# SERDES_10G0 register map
Vendor: Texas Instruments
Registers are 32-bit, access per field, reset 0x0 unless marked. A register's access mark holds for its fields unless they carry their own. Offsets are as the file gives them; [hi:lo] are bit positions.

## SERDES_10G0 (part 3 of 8)
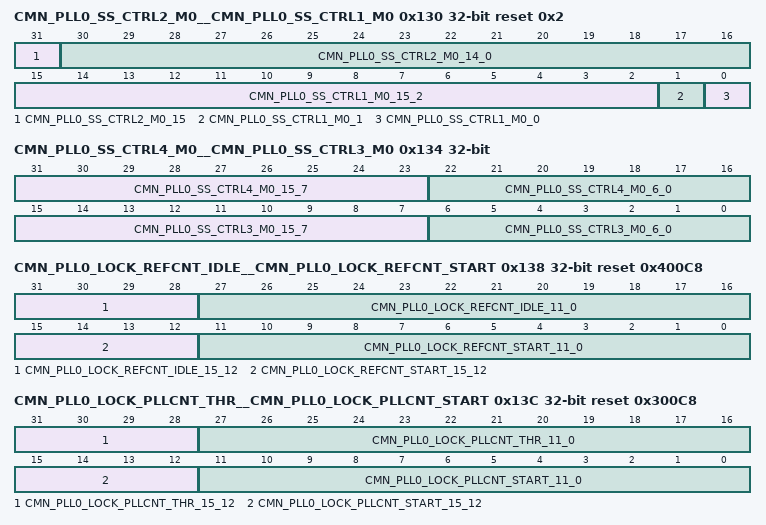
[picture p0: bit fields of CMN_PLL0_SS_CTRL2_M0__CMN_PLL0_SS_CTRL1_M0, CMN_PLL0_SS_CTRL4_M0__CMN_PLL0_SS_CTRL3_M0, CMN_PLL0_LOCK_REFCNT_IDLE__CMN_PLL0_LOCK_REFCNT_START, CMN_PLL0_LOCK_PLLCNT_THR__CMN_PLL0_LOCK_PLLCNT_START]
0x130 CMN_PLL0_SS_CTRL2_M0__CMN_PLL0_SS_CTRL1_M0 reset 0x2 — PLL 0 spread spectrum control register 1 mode 0
  [31] CMN_PLL0_SS_CTRL2_M0_15 ro — Reserved
  [30:16] CMN_PLL0_SS_CTRL2_M0_14_0 rw — Amplitude step size: Value of the amplitude_step_size pin on the spread spectrum waveform generator.
  [15:2] CMN_PLL0_SS_CTRL1_M0_15_2 ro — Reserved
  [1] CMN_PLL0_SS_CTRL1_M0_1 rw — Spread spectrum waveform generator disable: Setting this bit to a 1'b1 will disable the spread spectrum waveform generator.
  [0] CMN_PLL0_SS_CTRL1_M0_0 rw — Spread spectrum enable during VCO calibration : Setting this bit to a 1'b1 will enable the spread spectrum function while VCO calibration is taking place.
0x134 CMN_PLL0_SS_CTRL4_M0__CMN_PLL0_SS_CTRL3_M0 — PLL 0 spread spectrum control register 3 mode 0
  [31:23] CMN_PLL0_SS_CTRL4_M0_15_7 ro — Reserved
  [22:16] CMN_PLL0_SS_CTRL4_M0_6_0 rw — Time step size: Value for the time_step_size pin on the spread spectrum waveform generator.
  [15:7] CMN_PLL0_SS_CTRL3_M0_15_7 ro — Reserved
  [6:0] CMN_PLL0_SS_CTRL3_M0_6_0 rw — Number of steps: Value of the num_steps pin on the spread spectrum waveform generator.
0x138 CMN_PLL0_LOCK_REFCNT_IDLE__CMN_PLL0_LOCK_REFCNT_START reset 0x400C8 — PLL 0 lock reference counter start value register
  [31:28] CMN_PLL0_LOCK_REFCNT_IDLE_15_12 ro — Reserved
  [27:16] CMN_PLL0_LOCK_REFCNT_IDLE_11_0 rw — PLL lock reference counter idle value : This is the value used by the PLL lock detection logic to specify the number of reference clocks between each phase of counting PLL clocks.
  [15:12] CMN_PLL0_LOCK_REFCNT_START_15_12 ro — Reserved
  [11:0] CMN_PLL0_LOCK_REFCNT_START_11_0 rw — PLL lock reference counter start value : This is the value that is loaded into the PLL lock detect reference counter as the starting point for that counter, when checking for PLL lock.
0x13C CMN_PLL0_LOCK_PLLCNT_THR__CMN_PLL0_LOCK_PLLCNT_START reset 0x300C8 — PLL 0 lock PLL counter start value register
  [31:28] CMN_PLL0_LOCK_PLLCNT_THR_15_12 ro — Reserved
  [27:16] CMN_PLL0_LOCK_PLLCNT_THR_11_0 rw — PLL lock counter threshold value : This is the value used by the PLL lock detection logic to determine if the PLL has locked.
  [15:12] CMN_PLL0_LOCK_PLLCNT_START_15_12 ro — Reserved
  [11:0] CMN_PLL0_LOCK_PLLCNT_START_11_0 rw — PLL lock PLL counter start value : This is the value that is loaded into the PLL lock detect PLL counter as the starting point for that counter, when checking for PLL lock.
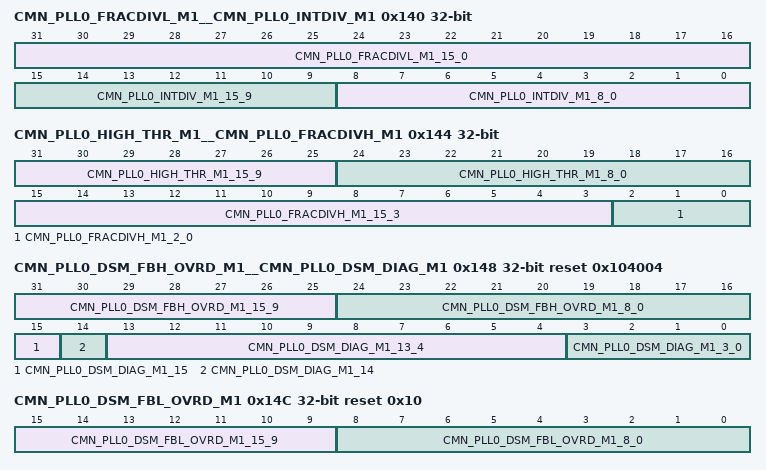
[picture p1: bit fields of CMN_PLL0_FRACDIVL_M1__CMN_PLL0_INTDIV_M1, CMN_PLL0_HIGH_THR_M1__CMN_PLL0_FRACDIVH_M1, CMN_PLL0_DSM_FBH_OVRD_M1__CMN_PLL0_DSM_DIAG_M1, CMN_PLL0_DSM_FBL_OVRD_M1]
0x140 CMN_PLL0_FRACDIVL_M1__CMN_PLL0_INTDIV_M1 — PLL 0 feedback divider integer register mode 1
  [31:16] CMN_PLL0_FRACDIVL_M1_15_0 rw — pll_fb_div_fractional: Value of the pll_fb_div_fractional[15:0] signal.
  [15:9] CMN_PLL0_INTDIV_M1_15_9 ro — Reserved
  [8:0] CMN_PLL0_INTDIV_M1_8_0 rw — pll_fb_div_integer value: Value of the pll_fb_div_integer signal.
0x144 CMN_PLL0_HIGH_THR_M1__CMN_PLL0_FRACDIVH_M1 — PLL 0 feedback divider fractional high register mode 1
  [31:25] CMN_PLL0_HIGH_THR_M1_15_9 ro — Reserved
  [24:16] CMN_PLL0_HIGH_THR_M1_8_0 rw — pll_fb_div_high_theshold: Value of the pll_fb_div_high_threshold signal.
  [15:3] CMN_PLL0_FRACDIVH_M1_15_3 ro — Reserved
  [2:0] CMN_PLL0_FRACDIVH_M1_2_0 rw — pll_fb_div_fractional: Value of the pll_fb_div_fractional[18:16] signal.
0x148 CMN_PLL0_DSM_FBH_OVRD_M1__CMN_PLL0_DSM_DIAG_M1 reset 0x104004 — PLL 0 delta sigma modulator diagnostics register mode 1
  [31:25] CMN_PLL0_DSM_FBH_OVRD_M1_15_9 ro — Reserved
  [24:16] CMN_PLL0_DSM_FBH_OVRD_M1_8_0 rw — PLL feedback divider high override value : When enabled by the PLL feedback divider override enable bit in the PLL 0 delta sigma modulator diagnostics register mode 0 on page 102, the value in this field will be used to override the value on the cmnda_pll0_fb_div_high signal.
  [15] CMN_PLL0_DSM_DIAG_M1_15 rw — Delta sigma bypass enable: When set to 1'b1, the delta sigma modulator will be bypassed, and the output will be the value specified for the internal pll_fb_div_integer signal.
  [14] CMN_PLL0_DSM_DIAG_M1_14 rw — PLL feedback divider override enable : When active (1'b1), the feedback divider low and high override values in the PLL 0 delta sigma modulator feedback divider value high override register mode 0 on page 102 and PLL 0 delta sigma modulator feedback divider value low override register mode 0 on page 102 registers will be used to override the feedback divider values driven to the analog.
  [13:4] CMN_PLL0_DSM_DIAG_M1_13_4 ro — Reserved
  [3:0] CMN_PLL0_DSM_DIAG_M1_3_0 rw — PLL feedback divider latency adjustment: This signal specifies a value to be subtracted from the feedback divider settings before they are output on the cmnda_pll0_fb_div_high and cmnda_pll0_fb_div_low signals.
0x14C CMN_PLL0_DSM_FBL_OVRD_M1 reset 0x10 — PLL 0 delta sigma modulator feedback divider value low override register mode 1
  [15:9] CMN_PLL0_DSM_FBL_OVRD_M1_15_9 ro — Reserved
  [8:0] CMN_PLL0_DSM_FBL_OVRD_M1_8_0 rw — PLL feedback divider low override value : When enabled by the PLL feedback divider override enable bit in the PLL 0 delta sigma modulator diagnostics register mode 0 on page 102, the value in this field will be used to override the value on the cmnda_pll0_fb_div_low signal.
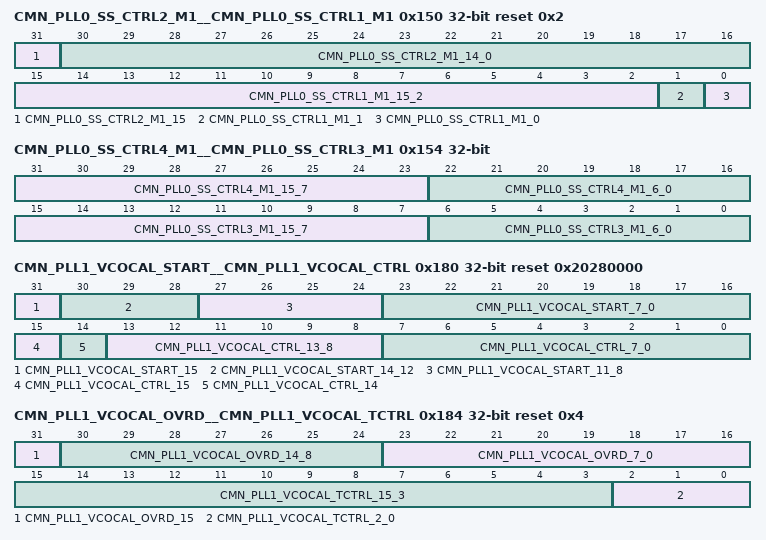
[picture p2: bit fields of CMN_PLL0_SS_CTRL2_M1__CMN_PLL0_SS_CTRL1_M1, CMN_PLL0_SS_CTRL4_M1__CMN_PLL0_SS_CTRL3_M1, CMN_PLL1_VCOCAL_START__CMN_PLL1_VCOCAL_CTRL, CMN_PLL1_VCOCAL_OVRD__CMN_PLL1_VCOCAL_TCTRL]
0x150 CMN_PLL0_SS_CTRL2_M1__CMN_PLL0_SS_CTRL1_M1 reset 0x2 — PLL 0 spread spectrum control register 1 mode 1
  [31] CMN_PLL0_SS_CTRL2_M1_15 ro — Reserved
  [30:16] CMN_PLL0_SS_CTRL2_M1_14_0 rw — Amplitude step size: Value of the amplitude_step_size pin on the spread spectrum waveform generator.
  [15:2] CMN_PLL0_SS_CTRL1_M1_15_2 ro — Reserved
  [1] CMN_PLL0_SS_CTRL1_M1_1 rw — Spread spectrum waveform generator disable: Setting this bit to a 1'b1 will disable the spread spectrum waveform generator.
  [0] CMN_PLL0_SS_CTRL1_M1_0 rw — Spread spectrum enable during VCO calibration : Setting this bit to a 1'b1 will enable the spread spectrum function while VCO calibration is taking place.
0x154 CMN_PLL0_SS_CTRL4_M1__CMN_PLL0_SS_CTRL3_M1 — PLL 0 spread spectrum control register 3 mode 1
  [31:23] CMN_PLL0_SS_CTRL4_M1_15_7 ro — Reserved
  [22:16] CMN_PLL0_SS_CTRL4_M1_6_0 rw — Time step size: Value for the time_step_size pin on the spread spectrum waveform generator.
  [15:7] CMN_PLL0_SS_CTRL3_M1_15_7 ro — Reserved
  [6:0] CMN_PLL0_SS_CTRL3_M1_6_0 rw — Number of steps: Value of the num_steps pin on the spread spectrum waveform generator.
0x180 CMN_PLL1_VCOCAL_START__CMN_PLL1_VCOCAL_CTRL reset 0x20280000 — PLL 1 VCO calibration control register
  [31] CMN_PLL1_VCOCAL_START_15 ro — Reserved
  [30:28] CMN_PLL1_VCOCAL_START_14_12 rw — VCO calibration initial step size control: This field specifies the initial step size for the VCO calibration state machine.
  [27:24] CMN_PLL1_VCOCAL_START_11_8 ro — Reserved
  [23:16] CMN_PLL1_VCOCAL_START_7_0 rw — VCO calibration code starting point value: This field specifies the starting VCO code that is used by the VCO calibration state machine.
  [15] CMN_PLL1_VCOCAL_CTRL_15 rw — Start VCO calibration: Activating (1'b1) this bit will start a VCO calibration process.
  [14] CMN_PLL1_VCOCAL_CTRL_14 ro — VCO calibration process done: This bit will be set to 1'b1 when the VCO calibration process is complete.
  [13:8] CMN_PLL1_VCOCAL_CTRL_13_8 ro — Reserved
  [7:0] CMN_PLL1_VCOCAL_CTRL_7_0 ro — VCO calibration code: This is the calibration code that was determined by the VCO calibration process.
0x184 CMN_PLL1_VCOCAL_OVRD__CMN_PLL1_VCOCAL_TCTRL reset 0x4 — PLL 1 VCO calibration timer control register
  [31] CMN_PLL1_VCOCAL_OVRD_15 rw — VCO calibration code override enable: Activating (1'b1) this bit allows the VCO code determined during the automatic VCO calibration process to be overridden by the value driven by the VCO calibration code override value field in this register.
  [30:24] CMN_PLL1_VCOCAL_OVRD_14_8 ro — Reserved
  [23:16] CMN_PLL1_VCOCAL_OVRD_7_0 rw — VCO calibration code override value: This field is used to override the VCO code determined during the automatic VCO calibration process.
  [15:3] CMN_PLL1_VCOCAL_TCTRL_15_3 ro — Reserved
  [2:0] CMN_PLL1_VCOCAL_TCTRL_2_0 rw — VCO calibration initial time scale control: This field specifies the calibration start time scaling factor applied to the VCO calibration when running the initial step size for the calibration code if not set to 1.
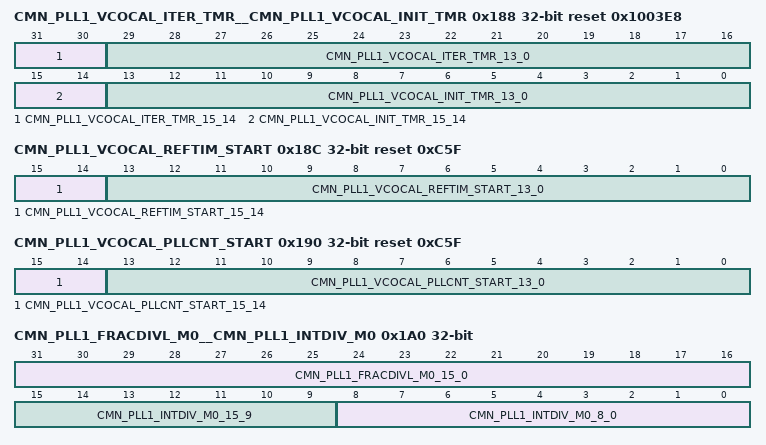
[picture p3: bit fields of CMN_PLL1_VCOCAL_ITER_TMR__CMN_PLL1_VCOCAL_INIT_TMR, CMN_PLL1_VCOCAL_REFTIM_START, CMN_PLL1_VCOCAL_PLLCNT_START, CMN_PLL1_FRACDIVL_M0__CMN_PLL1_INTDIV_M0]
0x188 CMN_PLL1_VCOCAL_ITER_TMR__CMN_PLL1_VCOCAL_INIT_TMR reset 0x1003E8 — PLL 1 VCO calibration initialization timer register
  [31:30] CMN_PLL1_VCOCAL_ITER_TMR_15_14 ro — Reserved
  [29:16] CMN_PLL1_VCOCAL_ITER_TMR_13_0 rw — Iteration wait timer value: This is the number of clocks to wait between when a calibration code is driven to the analog, and when the clock rates are measured.
  [15:14] CMN_PLL1_VCOCAL_INIT_TMR_15_14 ro — Reserved
  [13:0] CMN_PLL1_VCOCAL_INIT_TMR_13_0 rw — Initialization wait timer value: This is the number of clocks to wait between when the analog VCO calibration circuits are enabled, and when the first calibration code is driven to the analog.
0x18C CMN_PLL1_VCOCAL_REFTIM_START reset 0xC5F — PLL 1 VCO calibration reference clock timer start value register
  [15:14] CMN_PLL1_VCOCAL_REFTIM_START_15_14 ro — Reserved
  [13:0] CMN_PLL1_VCOCAL_REFTIM_START_13_0 rw — PLL VCO calibration reference clock timer start value : This is the value that is loaded into the reference clock timer as the starting point for that timer, when running VCO calibration.
0x190 CMN_PLL1_VCOCAL_PLLCNT_START reset 0xC5F — PLL 1 VCO calibration PLL clock counter start value register
  [15:14] CMN_PLL1_VCOCAL_PLLCNT_START_15_14 ro — Reserved
  [13:0] CMN_PLL1_VCOCAL_PLLCNT_START_13_0 rw — PLL VCO calibration PLL clock counter start value : This is the value that is loaded into the PLL clock counter as the starting point for that counter, when running VCO calibration.
0x1A0 CMN_PLL1_FRACDIVL_M0__CMN_PLL1_INTDIV_M0 — PLL 1 feedback divider integer register mode 0
  [31:16] CMN_PLL1_FRACDIVL_M0_15_0 rw — pll_fb_div_fractional: Value of the pll_fb_div_fractional[15:0] signal.
  [15:9] CMN_PLL1_INTDIV_M0_15_9 ro — Reserved
  [8:0] CMN_PLL1_INTDIV_M0_8_0 rw — pll_fb_div_integer value: Value of the pll_fb_div_integer signal.
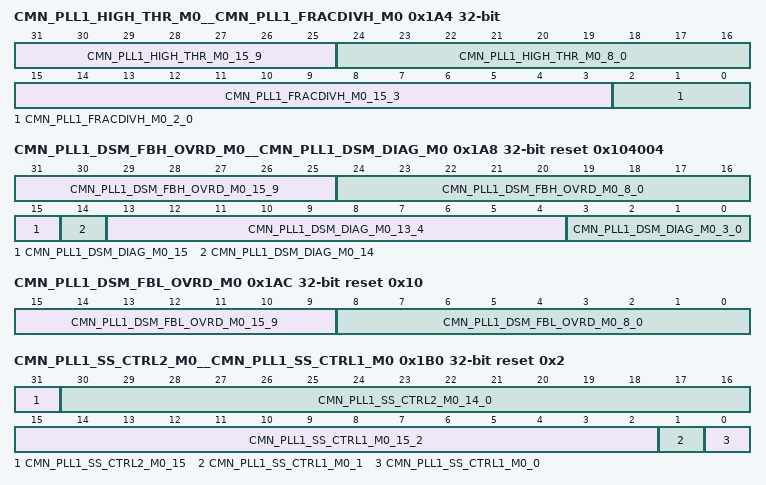
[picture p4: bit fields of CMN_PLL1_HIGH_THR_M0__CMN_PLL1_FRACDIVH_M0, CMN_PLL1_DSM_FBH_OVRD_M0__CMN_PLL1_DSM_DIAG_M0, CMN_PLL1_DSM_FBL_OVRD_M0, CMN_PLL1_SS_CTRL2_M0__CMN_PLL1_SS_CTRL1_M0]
0x1A4 CMN_PLL1_HIGH_THR_M0__CMN_PLL1_FRACDIVH_M0 — PLL 1 feedback divider fractional high register mode 0
  [31:25] CMN_PLL1_HIGH_THR_M0_15_9 ro — Reserved
  [24:16] CMN_PLL1_HIGH_THR_M0_8_0 rw — pll_fb_div_high_theshold: Value of the pll_fb_div_high_threshold signal.
  [15:3] CMN_PLL1_FRACDIVH_M0_15_3 ro — Reserved
  [2:0] CMN_PLL1_FRACDIVH_M0_2_0 rw — pll_fb_div_fractional: Value of the pll_fb_div_fractional[18:16] signal.
0x1A8 CMN_PLL1_DSM_FBH_OVRD_M0__CMN_PLL1_DSM_DIAG_M0 reset 0x104004 — PLL 1 delta sigma modulator diagnostics register mode 0
  [31:25] CMN_PLL1_DSM_FBH_OVRD_M0_15_9 ro — Reserved
  [24:16] CMN_PLL1_DSM_FBH_OVRD_M0_8_0 rw — PLL feedback divider high override value : When enabled by the PLL feedback divider override enable bit in the PLL 1 delta sigma modulator diagnostics register mode 0 on page 111, the value in this field will be used to override the value on the cmnda_pll1_fb_div_high signal.
  [15] CMN_PLL1_DSM_DIAG_M0_15 rw — Delta sigma bypass enable: When set to 1'b1, the delta sigma modulator will be bypassed, and the output will be the value specified for the internal pll_fb_div_integer signal.
  [14] CMN_PLL1_DSM_DIAG_M0_14 rw — PLL feedback divider override enable : When active (1'b1), the feedback divider low and high override values in the PLL 1 delta sigma modulator feedback divider value high override register mode 0 on page 111 and PLL 1 delta sigma modulator feedback divider value low override register mode 0 on page 111 registers will be used to override the feedback divider values driven to the analog.
  [13:4] CMN_PLL1_DSM_DIAG_M0_13_4 ro — Reserved
  [3:0] CMN_PLL1_DSM_DIAG_M0_3_0 rw — PLL feedback divider latency adjustment: This signal specifies a value to be subtracted from the feedback divider settings before they are output on the cmnda_pll1_fb_div_high and cmnda_pll1_fb_div_low signals.
0x1AC CMN_PLL1_DSM_FBL_OVRD_M0 reset 0x10 — PLL 1 delta sigma modulator feedback divider value low override register mode 0
  [15:9] CMN_PLL1_DSM_FBL_OVRD_M0_15_9 ro — Reserved
  [8:0] CMN_PLL1_DSM_FBL_OVRD_M0_8_0 rw — PLL feedback divider low override value : When enabled by the PLL feedback divider override enable bit in the PLL 1 delta sigma modulator diagnostics register mode 0 on page 111, the value in this field will be used to override the value on the cmnda_pll1_fb_div_low signal.
0x1B0 CMN_PLL1_SS_CTRL2_M0__CMN_PLL1_SS_CTRL1_M0 reset 0x2 — PLL 1 spread spectrum control register 1 mode 0
  [31] CMN_PLL1_SS_CTRL2_M0_15 ro — Reserved
  [30:16] CMN_PLL1_SS_CTRL2_M0_14_0 rw — Amplitude step size: Value of the amplitude_step_size pin on the spread spectrum waveform generator.
  [15:2] CMN_PLL1_SS_CTRL1_M0_15_2 ro — Reserved
  [1] CMN_PLL1_SS_CTRL1_M0_1 rw — Spread spectrum waveform generator disable: Setting this bit to a 1'b1 will disable the spread spectrum waveform generator.
  [0] CMN_PLL1_SS_CTRL1_M0_0 rw — Spread spectrum enable during VCO calibration : Setting this bit to a 1'b1 will enable the spread spectrum function while VCO calibration is taking place.
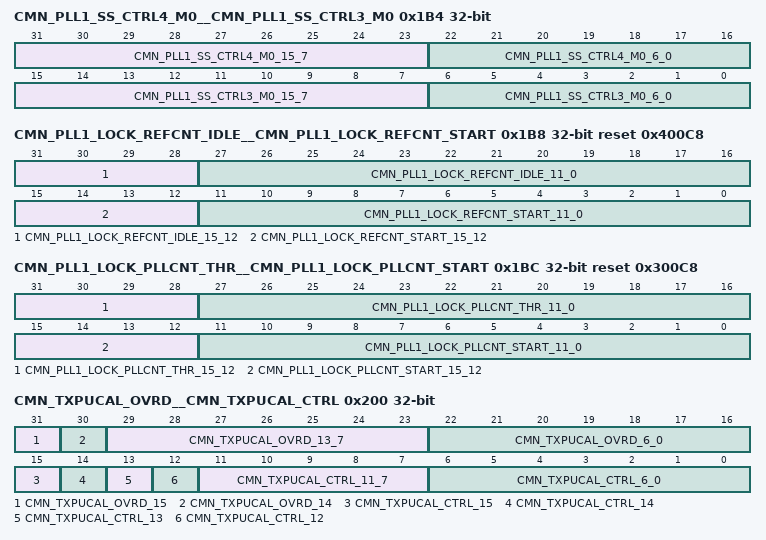
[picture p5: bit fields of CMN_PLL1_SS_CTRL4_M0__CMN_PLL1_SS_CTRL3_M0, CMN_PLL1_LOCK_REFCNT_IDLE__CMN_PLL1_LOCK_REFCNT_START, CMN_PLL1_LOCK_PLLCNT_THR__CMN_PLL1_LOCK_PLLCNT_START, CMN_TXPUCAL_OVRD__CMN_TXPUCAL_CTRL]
0x1B4 CMN_PLL1_SS_CTRL4_M0__CMN_PLL1_SS_CTRL3_M0 — PLL 1 spread spectrum control register 3 mode 0
  [31:23] CMN_PLL1_SS_CTRL4_M0_15_7 ro — Reserved
  [22:16] CMN_PLL1_SS_CTRL4_M0_6_0 rw — Time step size: Value for the time_step_size pin on the spread spectrum waveform generator.
  [15:7] CMN_PLL1_SS_CTRL3_M0_15_7 ro — Reserved
  [6:0] CMN_PLL1_SS_CTRL3_M0_6_0 rw — Number of steps: Value of the num_steps pin on the spread spectrum waveform generator.
0x1B8 CMN_PLL1_LOCK_REFCNT_IDLE__CMN_PLL1_LOCK_REFCNT_START reset 0x400C8 — PLL 1 lock reference counter start value register
  [31:28] CMN_PLL1_LOCK_REFCNT_IDLE_15_12 ro — Reserved
  [27:16] CMN_PLL1_LOCK_REFCNT_IDLE_11_0 rw — PLL lock reference counter idle value : This is the value used by the PLL lock detection logic to specify the number of reference clocks between each phase of counting PLL clocks.
  [15:12] CMN_PLL1_LOCK_REFCNT_START_15_12 ro — Reserved
  [11:0] CMN_PLL1_LOCK_REFCNT_START_11_0 rw — PLL lock reference counter start value : This is the value that is loaded into the PLL lock detect reference counter as the starting point for that counter, when checking for PLL lock.
0x1BC CMN_PLL1_LOCK_PLLCNT_THR__CMN_PLL1_LOCK_PLLCNT_START reset 0x300C8 — PLL 1 lock PLL counter start value register
  [31:28] CMN_PLL1_LOCK_PLLCNT_THR_15_12 ro — Reserved
  [27:16] CMN_PLL1_LOCK_PLLCNT_THR_11_0 rw — PLL lock counter threshold value : This is the value used by the PLL lock detection logic to determine if the PLL has locked.
  [15:12] CMN_PLL1_LOCK_PLLCNT_START_15_12 ro — Reserved
  [11:0] CMN_PLL1_LOCK_PLLCNT_START_11_0 rw — PLL lock PLL counter start value : This is the value that is loaded into the PLL lock detect PLL counter as the starting point for that counter, when checking for PLL lock.
0x200 CMN_TXPUCAL_OVRD__CMN_TXPUCAL_CTRL — TX pull-up resistor calibration control register
  [31] CMN_TXPUCAL_OVRD_15 rw — Resistor code override enable: Activation (1'b1) of this register bit allows the resistor codes determined during the automatic resistor calibration process to be overridden.
  [30] CMN_TXPUCAL_OVRD_14 rw — Analog calibration enable override: Activation (1'b1) of this register bit will force the analog calibration circuits to be enabled by activating the cmnda_rescal_en_tx_useg enable and the cmnda_rescal_clk_tx_useg clock.
  [29:23] CMN_TXPUCAL_OVRD_13_7 ro — Reserved
  [22:16] CMN_TXPUCAL_OVRD_6_0 rw — Resistor code override value: These bits are used to override the resistor code determined during the automatic resistor calibration process.
  [15] CMN_TXPUCAL_CTRL_15 rw — Start resistor calibration: Activating (1'b1) this bit will start the resistor calibration process.
  [14] CMN_TXPUCAL_CTRL_14 ro — Resistor calibration process done: This bit will be set to 1'b1 when the resistor calibration process is complete.
  [13] CMN_TXPUCAL_CTRL_13 ro — No analog calibration response : This signal indicates that the calibration function has gone through the entire calibration process, reached the final calibration value, and the analog has not responded indicating that a valid calibration value has been reached.
  [12] CMN_TXPUCAL_CTRL_12 ro — Current analog comparator response: This is the current state of the analog comparator response signal (cmnda_rescal_comp_tx_useg).
  [11:7] CMN_TXPUCAL_CTRL_11_7 ro — Reserved
  [6:0] CMN_TXPUCAL_CTRL_6_0 ro — Resistor calibration code: This is the calibration code that was determined by the resistor calibration process.
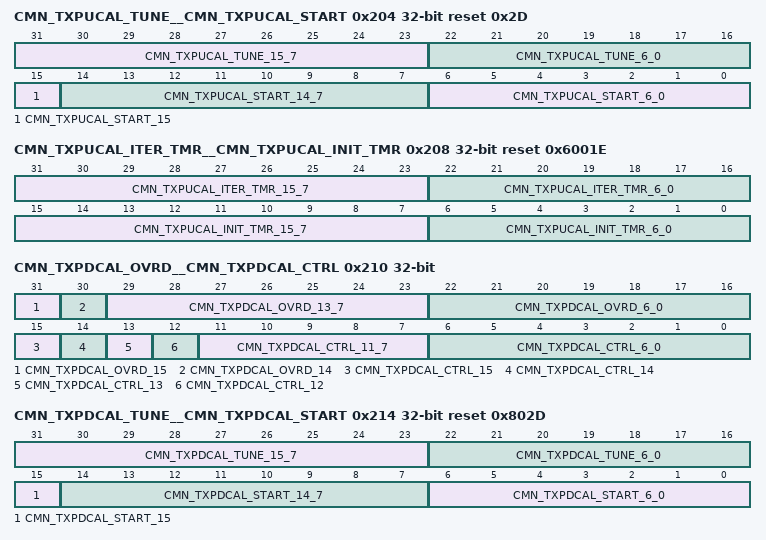
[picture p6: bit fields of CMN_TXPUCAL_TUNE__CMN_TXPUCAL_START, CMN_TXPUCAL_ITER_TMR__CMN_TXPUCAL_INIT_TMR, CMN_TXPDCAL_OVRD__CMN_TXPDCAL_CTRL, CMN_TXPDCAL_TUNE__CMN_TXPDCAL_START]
0x204 CMN_TXPUCAL_TUNE__CMN_TXPUCAL_START reset 0x2D — TX pull-up resistor calibration start register
  [31:23] CMN_TXPUCAL_TUNE_15_7 ro — Reserved
  [22:16] CMN_TXPUCAL_TUNE_6_0 rw — Resistor calibration tune value: The value of this field is added to the automatically calibrated code, or the override code if override is enabled.
  [15] CMN_TXPUCAL_START_15 rw — Resistor calibration direction: This controls the direction that the automatic calibration process steps the calibration codes in.
  [14:7] CMN_TXPUCAL_START_14_7 ro — Reserved
  [6:0] CMN_TXPUCAL_START_6_0 rw — Start resistor calibration code: This is the calibration code that the resistor calibration process starts with when automatic calibration is run.
0x208 CMN_TXPUCAL_ITER_TMR__CMN_TXPUCAL_INIT_TMR reset 0x6001E — TX pull-up resistor calibration initialization timer register
  [31:23] CMN_TXPUCAL_ITER_TMR_15_7 ro — Reserved
  [22:16] CMN_TXPUCAL_ITER_TMR_6_0 rw — Iteration wait timer value: This is the number of cmn_ref_clk clocks to wait between when a value is placed on the resistor selection bus going to the analog, and when the comparator value coming from the analog circuits can be checked.
  [15:7] CMN_TXPUCAL_INIT_TMR_15_7 ro — Reserved
  [6:0] CMN_TXPUCAL_INIT_TMR_6_0 rw — Initialization wait timer value: This is the number of cmn_ref_clk clocks to wait between when the analog resistor calibration circuits are enabled, and when the first resistor selection values are placed on the resistor selection bus, going to the analog.
0x210 CMN_TXPDCAL_OVRD__CMN_TXPDCAL_CTRL — TX pull-down resistor calibration control register
  [31] CMN_TXPDCAL_OVRD_15 rw — Resistor code override enable: Activation (1'b1) of this register bit allows the resistor codes determined during the automatic resistor calibration process to be overridden.
  [30] CMN_TXPDCAL_OVRD_14 rw — Analog calibration enable override: Activation (1'b1) of this register bit will force the analog calibration circuits to be enabled by activating the cmnda_rescal_en_tx_dseg enable and the cmnda_rescal_clk_tx_dseg clock.
  [29:23] CMN_TXPDCAL_OVRD_13_7 ro — Reserved
  [22:16] CMN_TXPDCAL_OVRD_6_0 rw — Resistor code override value: These bits are used to override the resistor code determined during the automatic resistor calibration process.
  [15] CMN_TXPDCAL_CTRL_15 rw — Start resistor calibration: Activating (1'b1) this bit will start the resistor calibration process.
  [14] CMN_TXPDCAL_CTRL_14 ro — Resistor calibration process done: This bit will be set to 1'b1 when the resistor calibration process is complete.
  [13] CMN_TXPDCAL_CTRL_13 ro — No analog calibration response : This signal indicates that the calibration function has gone through the entire calibration process, reached the final calibration value, and the analog has not responded indicating that a valid calibration value has been reached.
  [12] CMN_TXPDCAL_CTRL_12 ro — Current analog comparator response: This is the current state of the analog comparator response signal (cmnda_rescal_comp_tx_dseg).
  [11:7] CMN_TXPDCAL_CTRL_11_7 ro — Reserved
  [6:0] CMN_TXPDCAL_CTRL_6_0 ro — Resistor calibration code: This is the calibration code that was determined by the resistor calibration process.
0x214 CMN_TXPDCAL_TUNE__CMN_TXPDCAL_START reset 0x802D — TX pull-down resistor calibration start register
  [31:23] CMN_TXPDCAL_TUNE_15_7 ro — Reserved
  [22:16] CMN_TXPDCAL_TUNE_6_0 rw — Resistor calibration tune value: The value of this field is added to the automatically calibrated code, or the override code if override is enabled.
  [15] CMN_TXPDCAL_START_15 rw — Resistor calibration direction: This controls the direction that the automatic calibration process steps the calibration codes in.
  [14:7] CMN_TXPDCAL_START_14_7 ro — Reserved
  [6:0] CMN_TXPDCAL_START_6_0 rw — Start resistor calibration code: This is the calibration code that the resistor calibration process starts with when automatic calibration is run.
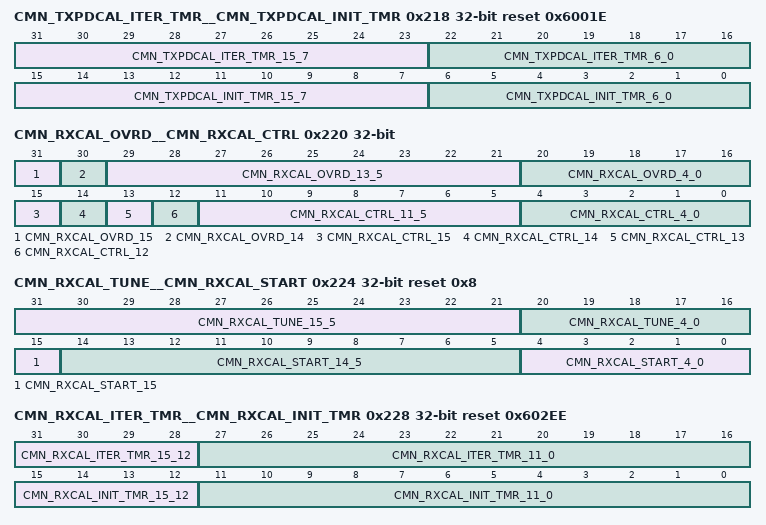
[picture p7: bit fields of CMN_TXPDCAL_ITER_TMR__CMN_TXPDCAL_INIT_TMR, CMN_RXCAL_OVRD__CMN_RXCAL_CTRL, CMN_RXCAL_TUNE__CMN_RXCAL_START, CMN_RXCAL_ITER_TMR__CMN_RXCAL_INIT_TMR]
0x218 CMN_TXPDCAL_ITER_TMR__CMN_TXPDCAL_INIT_TMR reset 0x6001E — TX pull-down resistor calibration initialization timer register
  [31:23] CMN_TXPDCAL_ITER_TMR_15_7 ro — Reserved
  [22:16] CMN_TXPDCAL_ITER_TMR_6_0 rw — Iteration wait timer value: This is the number of cmn_ref_clk clocks to wait between when a value is placed on the resistor selection bus going to the analog, and when the comparator value coming from the analog circuits can be checked.
  [15:7] CMN_TXPDCAL_INIT_TMR_15_7 ro — Reserved
  [6:0] CMN_TXPDCAL_INIT_TMR_6_0 rw — Initialization wait timer value: This is the number of cmn_ref_clk clocks to wait between when the analog resistor calibration circuits are enabled, and when the first resistor selection values are placed on the resistor selection bus, going to the analog.
0x220 CMN_RXCAL_OVRD__CMN_RXCAL_CTRL — RX resistor calibration control register
  [31] CMN_RXCAL_OVRD_15 rw — Resistor code override enable: Activation (1'b1) of this register bit allows the resistor codes determined during the automatic resistor calibration process to be overridden.
  [30] CMN_RXCAL_OVRD_14 rw — Analog calibration enable override: Activation (1'b1) of this register bit will force the analog calibration circuits to be enabled by activating the cmnda_rescal_en_rx enable and the cmnda_rescal_clk_rx clock.
  [29:21] CMN_RXCAL_OVRD_13_5 ro — Reserved
  [20:16] CMN_RXCAL_OVRD_4_0 rw — Resistor code override value: These bits are used to override the resistor code determined during the automatic resistor calibration process.
  [15] CMN_RXCAL_CTRL_15 rw — Start resistor calibration: Activating (1'b1) this bit will start the resistor calibration process.
  [14] CMN_RXCAL_CTRL_14 ro — Resistor calibration process done: This bit will be set to 1'b1 when the resistor calibration process is complete.
  [13] CMN_RXCAL_CTRL_13 ro — No analog calibration response : This signal indicates that the calibration function has gone through the entire calibration process, reached the final calibration value, and the analog has not responded indicating that a valid calibration value has been reached.
  [12] CMN_RXCAL_CTRL_12 ro — Current analog comparator response: This is the current state of the analog comparator response signal (cmnda_rescal_comp_rx).
  [11:5] CMN_RXCAL_CTRL_11_5 ro — Reserved
  [4:0] CMN_RXCAL_CTRL_4_0 ro — Resistor calibration code: This is the calibration code that was determined by the resistor calibration process.
0x224 CMN_RXCAL_TUNE__CMN_RXCAL_START reset 0x8 — RX resistor calibration start register
  [31:21] CMN_RXCAL_TUNE_15_5 ro — Reserved
  [20:16] CMN_RXCAL_TUNE_4_0 rw — Resistor calibration tune value: The value of this field is added to the automatically calibrated code, or the override code if override is enabled.
  [15] CMN_RXCAL_START_15 rw — Resistor calibration direction: This controls the direction that the automatic calibration process steps the calibration codes in.
  [14:5] CMN_RXCAL_START_14_5 ro — Reserved
  [4:0] CMN_RXCAL_START_4_0 rw — Start resistor calibration code: This is the calibration code that the resistor calibration process starts with when automatic calibration is run.
0x228 CMN_RXCAL_ITER_TMR__CMN_RXCAL_INIT_TMR reset 0x602EE — RX resistor calibration initialization timer register
  [31:28] CMN_RXCAL_ITER_TMR_15_12 ro — Reserved
  [27:16] CMN_RXCAL_ITER_TMR_11_0 rw — Iteration wait timer value: This is the number of cmn_ref_clk clocks to wait between when a value is placed on the resistor selection bus going to the analog, and when the comparator value coming from the analog circuits can be checked.
  [15:12] CMN_RXCAL_INIT_TMR_15_12 ro — Reserved
  [11:0] CMN_RXCAL_INIT_TMR_11_0 rw — Initialization wait timer value: This is the number of cmn_ref_clk clocks to wait between when the analog resistor calibration circuits are enabled, and when the first resistor selection values are placed on the resistor selection bus, going to the analog.
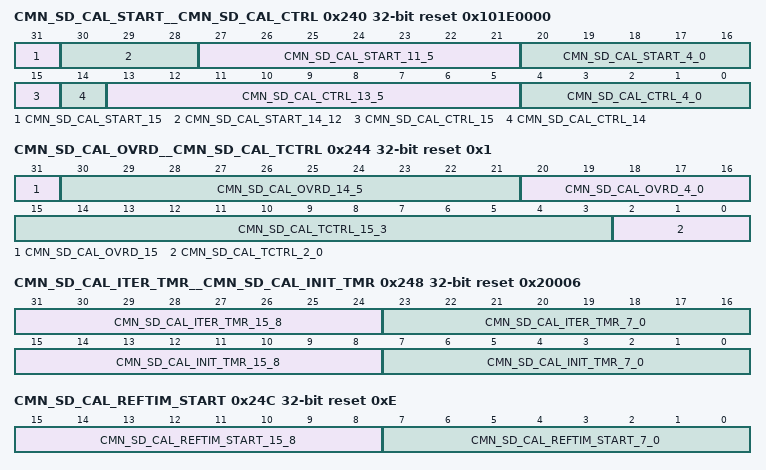
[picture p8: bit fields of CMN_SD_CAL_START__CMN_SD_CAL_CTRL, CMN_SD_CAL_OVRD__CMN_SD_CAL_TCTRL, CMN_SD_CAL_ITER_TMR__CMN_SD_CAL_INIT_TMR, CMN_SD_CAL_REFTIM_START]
0x240 CMN_SD_CAL_START__CMN_SD_CAL_CTRL reset 0x101E0000 — Signal detect clock calibration control register
  [31] CMN_SD_CAL_START_15 ro — Reserved
  [30:28] CMN_SD_CAL_START_14_12 rw — Calibration initial step size control: This field specifies the initial step size for the calibration state machine.
  [27:21] CMN_SD_CAL_START_11_5 ro — Reserved
  [20:16] CMN_SD_CAL_START_4_0 rw — Calibration code starting point value: This field specifies the starting code that is used by the calibration state machine.
  [15] CMN_SD_CAL_CTRL_15 rw — Start calibration: Activating (1'b1) this bit will start a calibration process.
  [14] CMN_SD_CAL_CTRL_14 ro — Calibration process done: This bit will be set to 1'b1 when the calibration process is complete.
  [13:5] CMN_SD_CAL_CTRL_13_5 ro — Reserved
  [4:0] CMN_SD_CAL_CTRL_4_0 ro — Calibration code: This is the calibration code that was determined by the calibration process.
0x244 CMN_SD_CAL_OVRD__CMN_SD_CAL_TCTRL reset 0x1 — Signal detect clock calibration timer control register
  [31] CMN_SD_CAL_OVRD_15 rw — Calibration code override enable: Activating (1'b1) this bit allows the code determined during the automatic calibration process to be overridden by the value driven by the calibration code override value field in this register.
  [30:21] CMN_SD_CAL_OVRD_14_5 ro — Reserved
  [20:16] CMN_SD_CAL_OVRD_4_0 rw — Calibration code override value: This field is used to override the code determined during the automatic calibration process.
  [15:3] CMN_SD_CAL_TCTRL_15_3 ro — Reserved
  [2:0] CMN_SD_CAL_TCTRL_2_0 rw — Calibration initial time scale control: This field specifies the calibration start time scaling factor applied to the calibration when running the initial step size for the calibration code is not set to 1.
0x248 CMN_SD_CAL_ITER_TMR__CMN_SD_CAL_INIT_TMR reset 0x20006 — Signal detect clock calibration initialization timer register
  [31:24] CMN_SD_CAL_ITER_TMR_15_8 ro — Reserved
  [23:16] CMN_SD_CAL_ITER_TMR_7_0 rw — Iteration wait timer value: This is the number of clocks to wait between when a calibration code is driven to the analog, and when the clock rates are measured.
  [15:8] CMN_SD_CAL_INIT_TMR_15_8 ro — Reserved
  [7:0] CMN_SD_CAL_INIT_TMR_7_0 rw — Initialization wait timer value: This is the number of clocks to wait between when the analog calibration circuits are enabled, and when the first calibration code is driven to the analog.
0x24C CMN_SD_CAL_REFTIM_START reset 0xE — Signal detect clock calibration reference clock timer start value register
  [15:8] CMN_SD_CAL_REFTIM_START_15_8 ro — Reserved
  [7:0] CMN_SD_CAL_REFTIM_START_7_0 rw — Calibration reference clock timer start value : This is the value that is loaded into the reference clock timer as the starting point for that timer, when running calibration.
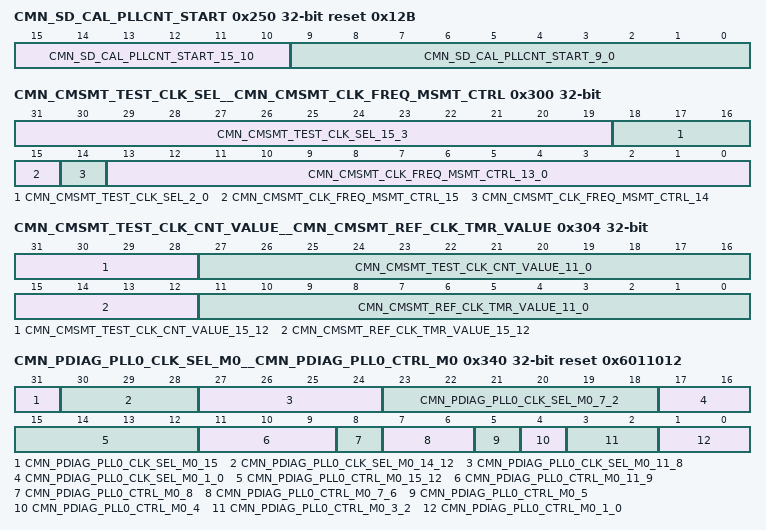
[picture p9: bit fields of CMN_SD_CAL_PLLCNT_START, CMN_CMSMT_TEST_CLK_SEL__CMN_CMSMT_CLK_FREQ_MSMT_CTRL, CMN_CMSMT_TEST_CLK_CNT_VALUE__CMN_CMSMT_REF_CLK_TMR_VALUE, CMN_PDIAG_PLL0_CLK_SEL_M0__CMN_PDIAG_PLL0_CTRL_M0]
0x250 CMN_SD_CAL_PLLCNT_START reset 0x12B — Signal detect clock calibration PLL clock counter start value register
  [15:10] CMN_SD_CAL_PLLCNT_START_15_10 ro — Reserved
  [9:0] CMN_SD_CAL_PLLCNT_START_9_0 rw — Calibration feedback clock counter start value : This is the value that is loaded into the PLL clock counter as the starting point for that counter, when running calibration.
0x300 CMN_CMSMT_TEST_CLK_SEL__CMN_CMSMT_CLK_FREQ_MSMT_CTRL — Clock frequency measurement control register
  [31:19] CMN_CMSMT_TEST_CLK_SEL_15_3 ro — Reserved
  [18:16] CMN_CMSMT_TEST_CLK_SEL_2_0 rw — Test clock select: This field drives the test_clk_select pin, in order to control an external MUX for selecting between multiple test clocks to measure.
  [15] CMN_CMSMT_CLK_FREQ_MSMT_CTRL_15 rw — Run test clock measurement: Activating (1'b1) this bit will run the test clock measurement process.
  [14] CMN_CMSMT_CLK_FREQ_MSMT_CTRL_14 ro — Test clock measurement done: This bit will be set to 1'b1 when the test clock measurement process is complete.
  [13:0] CMN_CMSMT_CLK_FREQ_MSMT_CTRL_13_0 ro — Reserved
0x304 CMN_CMSMT_TEST_CLK_CNT_VALUE__CMN_CMSMT_REF_CLK_TMR_VALUE — Reference clock timer value register
  [31:28] CMN_CMSMT_TEST_CLK_CNT_VALUE_15_12 ro — Reserved
  [27:16] CMN_CMSMT_TEST_CLK_CNT_VALUE_11_0 ro — Test clock counter value: When the test clock measurement process is complete, the value in this field specifies the number of test clock cycles that were counted in the time specified by the reference clock timer value.
  [15:12] CMN_CMSMT_REF_CLK_TMR_VALUE_15_12 ro — Reserved
  [11:0] CMN_CMSMT_REF_CLK_TMR_VALUE_11_0 rw — Reference clock timer value : This specifies the amount of time, in reference clock cycles, to count test clock cycles.
0x340 CMN_PDIAG_PLL0_CLK_SEL_M0__CMN_PDIAG_PLL0_CTRL_M0 reset 0x6011012 — PLL 0 control register mode 0
  [31] CMN_PDIAG_PLL0_CLK_SEL_M0_15 rw — PLL 0 clock 1 divider enable: This bit enables the divider used to generate the cmnda_pll0_clk_1, from the PLL high speed clock.
  [30:28] CMN_PDIAG_PLL0_CLK_SEL_M0_14_12 rw — PLL 0 clock 1 divider select: This field selects the divider value used to generate the cmnda_pll0_clk_1, from the PLL high speed clock, by driving the cmnda_pll0_clk_1_div_sel signal to the analog.
  [27:24] CMN_PDIAG_PLL0_CLK_SEL_M0_11_8 rw — PLL 0 clock 0 and derived reference clock divider select: This field selects the divider value used to generate the cmnda_pll0_clk_0 and derived reference clock, from the PLL high speed clock, by driving the cmnda_pll0_clk_0_div_sel signal to the analog.
  [23:18] CMN_PDIAG_PLL0_CLK_SEL_M0_7_2 ro — Reserved
  [17:16] CMN_PDIAG_PLL0_CLK_SEL_M0_1_0 rw — PLL 0 clock select: This field selects one of 3 possible high speed output clocks from PLL 0, to drive on the high speed analog clock 0, by driving the cmnda_pll0_clk_sel signal to the analog.
  [15:12] CMN_PDIAG_PLL0_CTRL_M0_15_12 rw — This field controls the Ring VCO Frequency drift with temperature.
  [11:9] CMN_PDIAG_PLL0_CTRL_M0_11_9 ro — Reserved
  [8] CMN_PDIAG_PLL0_CTRL_M0_8 rw — PLL VCO select: Selects the VCO mode of operation, by driving the cmnda_pll0_vco_sel signal going into the common analog.
  [7:6] CMN_PDIAG_PLL0_CTRL_M0_7_6 ro — Reserved
  [5] CMN_PDIAG_PLL0_CTRL_M0_5 rw — PLL feedback divider clock select: This signal selects which internal PLL clock will be used to drive the cmnda_pll0_fb_divider_clk, by driving the cmnda_pll0_fb_divider_clk_sel signal going into the common analog.
  [4] CMN_PDIAG_PLL0_CTRL_M0_4 rw — PLL feedback divider pre-scale: controls the feedback divider pre-scale, by driving the cmnda_pll0_div24_sel signal going into the common analog.
  [3:2] CMN_PDIAG_PLL0_CTRL_M0_3_2 ro — Reserved
  [1:0] CMN_PDIAG_PLL0_CTRL_M0_1_0 rw — PLL PFD reset delay: Controls the minimum reset pulse width for the PFD.
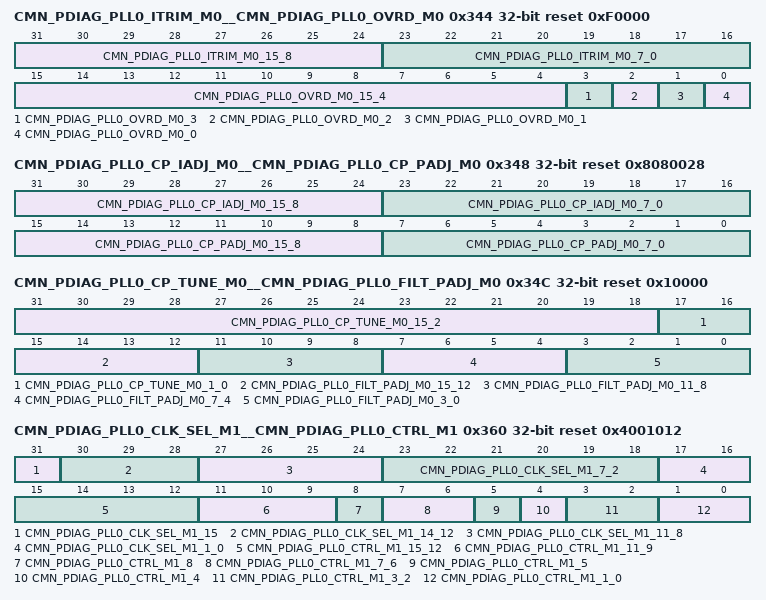
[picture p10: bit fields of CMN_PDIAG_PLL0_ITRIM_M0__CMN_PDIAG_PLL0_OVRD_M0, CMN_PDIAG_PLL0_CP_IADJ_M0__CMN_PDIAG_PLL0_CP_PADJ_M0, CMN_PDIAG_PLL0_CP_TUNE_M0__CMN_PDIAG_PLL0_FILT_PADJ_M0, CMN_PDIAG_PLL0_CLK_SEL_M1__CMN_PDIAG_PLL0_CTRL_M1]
0x344 CMN_PDIAG_PLL0_ITRIM_M0__CMN_PDIAG_PLL0_OVRD_M0 reset 0xF0000 — PLL 0 override register mode 0
  [31:24] CMN_PDIAG_PLL0_ITRIM_M0_15_8 ro — Reserved
  [23:16] CMN_PDIAG_PLL0_ITRIM_M0_7_0 rw — PLL VCO bias current trim code: Controls the tank currents in the PLL LC tank circuit.
  [15:4] CMN_PDIAG_PLL0_OVRD_M0_15_4 ro — Reserved
  [3] CMN_PDIAG_PLL0_OVRD_M0_3 rw — PLL VCO calibration enable override enable: When active (1'b1), the PLL VCO calibration enable override bit in this register, can be used to directly control the enable of the VCO calibration function in the PLL (instead of the VCO calibration module).
  [2] CMN_PDIAG_PLL0_OVRD_M0_2 rw — PLL VCO calibration enable override: When enabled by the PLL VCO calibration enable override enable bit in this register, this bit will directly control the enable of the VCO calibration function in the PLL.
  [1] CMN_PDIAG_PLL0_OVRD_M0_1 rw — PLL phase lock detect enable : Enables the diagnostic PLL phase lock detect function in the analog.
  [0] CMN_PDIAG_PLL0_OVRD_M0_0 ro — PLL phase lock detected : When enabled by the PLL phase lock detect enable bit in this register, this bit indicates that a PLL phase lock has been detected.
0x348 CMN_PDIAG_PLL0_CP_IADJ_M0__CMN_PDIAG_PLL0_CP_PADJ_M0 rw reset 0x8080028 — PLL 0 charge pump proportional path adjust register mode 0
  [31:24] CMN_PDIAG_PLL0_CP_IADJ_M0_15_8 — PLL charge pump integral path capacitance adjust: Adjusts the charge pump integral path capacitance, by driving the cmnda_pll0_cp_int_cap_adj signal going to the analog.
  [23:16] CMN_PDIAG_PLL0_CP_IADJ_M0_7_0 — PLL charge pump integral path current adjust: Adjusts the charge pump integral path current, by driving the cmnda_pll0_cp_int_cur_adj signal going to the analog.
  [15:8] CMN_PDIAG_PLL0_CP_PADJ_M0_15_8 — PLL charge pump proportional path capacitance adjust: Adjusts the charge pump proportional path capacitance, by driving the cmnda_pll0_cp_prop_cap_adj signal going to the analog.
  [7:0] CMN_PDIAG_PLL0_CP_PADJ_M0_7_0 — PLL charge pump proportional path current adjust: Adjusts the charge pump proportional path current, by driving the cmnda_pll0_cp_prop_cur_adj signal going to the analog.
0x34C CMN_PDIAG_PLL0_CP_TUNE_M0__CMN_PDIAG_PLL0_FILT_PADJ_M0 reset 0x10000 — PLL 0 proportional path filter adjust register mode 0
  [31:18] CMN_PDIAG_PLL0_CP_TUNE_M0_15_2 ro — Reserved
  [17:16] CMN_PDIAG_PLL0_CP_TUNE_M0_1_0 rw — PLL charge pump calibration reference voltage tune: Adjusts the charge pump calibration reference voltage, by driving the cmnda_pll0_cp_vref_tune signal going to the analog.
  [15:12] CMN_PDIAG_PLL0_FILT_PADJ_M0_15_12 ro — Reserved
  [11:8] CMN_PDIAG_PLL0_FILT_PADJ_M0_11_8 rw — PLL proportional path filter capacitance adjust: Adjusts the proportional path filter capacitance, by driving the cmnda_pll0_filt_c_adj signal going to the analog.
  [7:4] CMN_PDIAG_PLL0_FILT_PADJ_M0_7_4 ro — Reserved
  [3:0] CMN_PDIAG_PLL0_FILT_PADJ_M0_3_0 rw — PLL proportional path filter resistance adjust: Adjusts the proportional path filter resistance, by driving the cmnda_pll0_filt_r_adj signal going to the analog.
0x360 CMN_PDIAG_PLL0_CLK_SEL_M1__CMN_PDIAG_PLL0_CTRL_M1 reset 0x4001012 — PLL 0 control register mode 1
  [31] CMN_PDIAG_PLL0_CLK_SEL_M1_15 rw — PLL 0 clock 1 divider enable: This bit enables the divider used to generate the cmnda_pll0_clk_1, from the PLL high speed clock.
  [30:28] CMN_PDIAG_PLL0_CLK_SEL_M1_14_12 rw — PLL 0 clock 1 divider select: This field selects the divider value used to generate the cmnda_pll0_clk_1, from the PLL high speed clock, by driving the cmnda_pll0_clk_1_div_sel signal to the analog.
  [27:24] CMN_PDIAG_PLL0_CLK_SEL_M1_11_8 rw — PLL 0 clock 0 and derived reference clock divider select: This field selects the divider value used to generate the cmnda_pll0_clk_0 and derived reference clock, from the PLL high speed clock, by driving the cmnda_pll0_clk_0_div_sel signal to the analog.
  [23:18] CMN_PDIAG_PLL0_CLK_SEL_M1_7_2 ro — Reserved
  [17:16] CMN_PDIAG_PLL0_CLK_SEL_M1_1_0 rw — PLL 0 clock select: This field selects one of 3 possible high speed output clocks from PLL 0, to drive on the high speed analog clock 0, by driving the cmnda_pll0_clk_sel signal to the analog.
  [15:12] CMN_PDIAG_PLL0_CTRL_M1_15_12 rw — This field controls the Ring VCO Frequency drift with temperature.
  [11:9] CMN_PDIAG_PLL0_CTRL_M1_11_9 ro — Reserved
  [8] CMN_PDIAG_PLL0_CTRL_M1_8 rw — PLL VCO select: Selects the VCO mode of operation, by driving the cmnda_pll0_vco_sel signal going into the common analog.
  [7:6] CMN_PDIAG_PLL0_CTRL_M1_7_6 ro — Reserved
  [5] CMN_PDIAG_PLL0_CTRL_M1_5 rw — PLL feedback divider clock select: This signal selects which internal PLL clock will be used to drive the cmnda_pll0_fb_divider_clk,driving the cmnda_pll0_fb_divider_clk_sel signal going into the common analog.
  [4] CMN_PDIAG_PLL0_CTRL_M1_4 rw — PLL feedback divider pre-scale: controls the feedback divider pre-scale, by driving the cmnda_pll0_div24_sel signal going into the common analog.
  [3:2] CMN_PDIAG_PLL0_CTRL_M1_3_2 ro — Reserved
  [1:0] CMN_PDIAG_PLL0_CTRL_M1_1_0 rw — PLL PFD reset delay: Controls the minimum reset pulse width for the PFD.
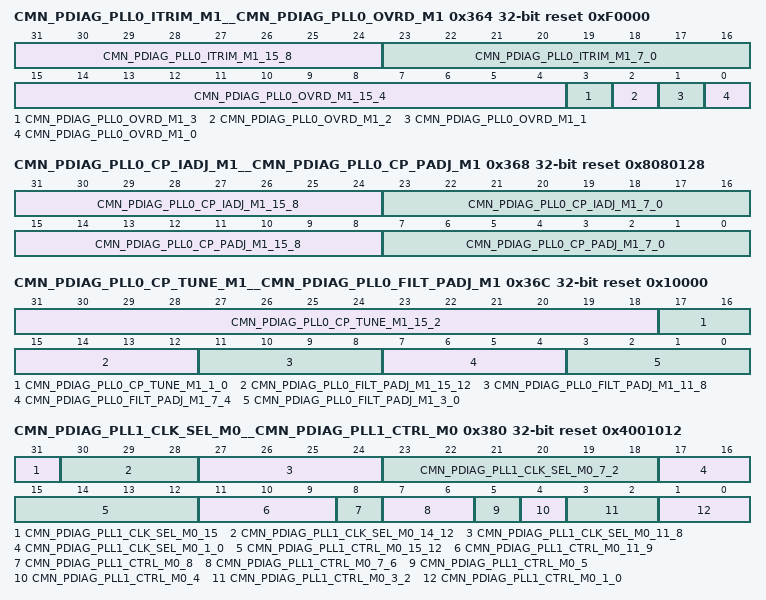
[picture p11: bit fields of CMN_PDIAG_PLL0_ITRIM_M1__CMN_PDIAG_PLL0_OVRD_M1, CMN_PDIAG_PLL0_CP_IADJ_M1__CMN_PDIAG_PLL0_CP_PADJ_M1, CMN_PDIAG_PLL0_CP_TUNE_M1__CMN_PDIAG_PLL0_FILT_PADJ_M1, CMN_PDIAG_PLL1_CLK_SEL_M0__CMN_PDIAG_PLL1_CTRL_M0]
0x364 CMN_PDIAG_PLL0_ITRIM_M1__CMN_PDIAG_PLL0_OVRD_M1 reset 0xF0000 — PLL 0 override register mode 1
  [31:24] CMN_PDIAG_PLL0_ITRIM_M1_15_8 ro — Reserved
  [23:16] CMN_PDIAG_PLL0_ITRIM_M1_7_0 rw — PLL VCO bias current trim code: Controls the tank currents in the PLL LC tank circuit.
  [15:4] CMN_PDIAG_PLL0_OVRD_M1_15_4 ro — Reserved
  [3] CMN_PDIAG_PLL0_OVRD_M1_3 rw — PLL VCO calibration enable override enable: When active (1'b1), the PLL VCO calibration enable override bit in this register, can be used to directly control the enable of the VCO calibration function in the PLL (instead of the VCO calibration module).
  [2] CMN_PDIAG_PLL0_OVRD_M1_2 rw — PLL VCO calibration enable override: When enabled by the PLL VCO calibration enable override enable bit in this register, this bit will directly control the enable of the VCO calibration function in the PLL.
  [1] CMN_PDIAG_PLL0_OVRD_M1_1 rw — PLL phase lock detect enable : Enables the diagnostic PLL phase lock detect function in the analog.
  [0] CMN_PDIAG_PLL0_OVRD_M1_0 ro — PLL phase lock detected : When enabled by the PLL phase lock detect enable bit in this register, this bit indicates that a PLL phase lock has been detected.
0x368 CMN_PDIAG_PLL0_CP_IADJ_M1__CMN_PDIAG_PLL0_CP_PADJ_M1 rw reset 0x8080128 — PLL 0 charge pump proportional path adjust register mode 1
  [31:24] CMN_PDIAG_PLL0_CP_IADJ_M1_15_8 — PLL charge pump integral path capacitance adjust: Adjusts the charge pump integral path capacitance, by driving the cmnda_pll0_cp_int_cap_adj signal going to the analog.
  [23:16] CMN_PDIAG_PLL0_CP_IADJ_M1_7_0 — PLL charge pump integral path current adjust: Adjusts the charge pump integral path current, by driving the cmnda_pll0_cp_int_cur_adj signal going to the analog.
  [15:8] CMN_PDIAG_PLL0_CP_PADJ_M1_15_8 — PLL charge pump proportional path capacitance adjust: Adjusts the charge pump proportional path capacitance, by driving the cmnda_pll0_cp_prop_cap_adj signal going to the analog.
  [7:0] CMN_PDIAG_PLL0_CP_PADJ_M1_7_0 — PLL charge pump proportional path current adjust: Adjusts the charge pump proportional path current, by driving the cmnda_pll0_cp_prop_cur_adj signal going to the analog.
0x36C CMN_PDIAG_PLL0_CP_TUNE_M1__CMN_PDIAG_PLL0_FILT_PADJ_M1 reset 0x10000 — PLL 0 proportional path filter adjust register mode 1
  [31:18] CMN_PDIAG_PLL0_CP_TUNE_M1_15_2 ro — Reserved
  [17:16] CMN_PDIAG_PLL0_CP_TUNE_M1_1_0 rw — PLL charge pump calibration reference voltage tune: Adjusts the charge pump calibration reference voltage, by driving the cmnda_pll0_cp_vref_tune signal going to the analog.
  [15:12] CMN_PDIAG_PLL0_FILT_PADJ_M1_15_12 ro — Reserved
  [11:8] CMN_PDIAG_PLL0_FILT_PADJ_M1_11_8 rw — PLL proportional path filter capacitance adjust: Adjusts the proportional path filter capacitance, by driving the cmnda_pll0_filt_c_adj signal going to the analog.
  [7:4] CMN_PDIAG_PLL0_FILT_PADJ_M1_7_4 ro — Reserved
  [3:0] CMN_PDIAG_PLL0_FILT_PADJ_M1_3_0 rw — PLL proportional path filter resistance adjust: Adjusts the proportional path filter resistance, by driving the cmnda_pll0_filt_r_adj signal going to the analog.
0x380 CMN_PDIAG_PLL1_CLK_SEL_M0__CMN_PDIAG_PLL1_CTRL_M0 reset 0x4001012 — PLL 1 control register mode 0
  [31] CMN_PDIAG_PLL1_CLK_SEL_M0_15 rw — PLL 1 clock 1 divider enable: This bit enables the divider used to generate the cmnda_pll1_clk_1, from the PLL high speed clock.
  [30:28] CMN_PDIAG_PLL1_CLK_SEL_M0_14_12 rw — PLL 1 clock 1 divider select: This field selects the divider value used to generate the cmnda_pll1_clk_1, from the PLL high speed clock, by driving the cmnda_pll1_clk_1_div_sel signal to the analog.
  [27:24] CMN_PDIAG_PLL1_CLK_SEL_M0_11_8 rw — PLL 1 clock 0 and derived reference clock divider select: This field selects the divider value used to generate the cmnda_pll1_clk_0 and derived reference clock, from the PLL high speed clock, by driving the cmnda_pll1_clk_0_div_sel signal to the analog.
  [23:18] CMN_PDIAG_PLL1_CLK_SEL_M0_7_2 ro — Reserved
  [17:16] CMN_PDIAG_PLL1_CLK_SEL_M0_1_0 rw — PLL 1 clock select: This field selects one of 3 possible high speed output clocks from PLL 1, to drive on the high speed analog clock 1, by driving the cmnda_pll1_clk_sel signal to the analog.
  [15:12] CMN_PDIAG_PLL1_CTRL_M0_15_12 rw — This field controls the Ring VCO Frequency drift with temperature.
  [11:9] CMN_PDIAG_PLL1_CTRL_M0_11_9 ro — Reserved
  [8] CMN_PDIAG_PLL1_CTRL_M0_8 rw — PLL VCO select: Selects the VCO mode of operation, by driving the cmnda_pll1_vco_sel signal going into the common analog.
  [7:6] CMN_PDIAG_PLL1_CTRL_M0_7_6 ro — Reserved
  [5] CMN_PDIAG_PLL1_CTRL_M0_5 rw — PLL feedback divider clock select: This signal selects which internal PLL clock will be used to drive the cmnda_pll1_fb_divider_clk,driving the cmnda_pll1_fb_divider_clk_sel signal going into the common analog.
  [4] CMN_PDIAG_PLL1_CTRL_M0_4 rw — PLL feedback divider pre-scale: controls the feedback divider pre-scale, by driving the cmnda_pll1_div24_sel signal going into the common analog.
  [3:2] CMN_PDIAG_PLL1_CTRL_M0_3_2 ro — Reserved
  [1:0] CMN_PDIAG_PLL1_CTRL_M0_1_0 rw — PLL PFD reset delay: Controls the minimum reset pulse width for the PFD.
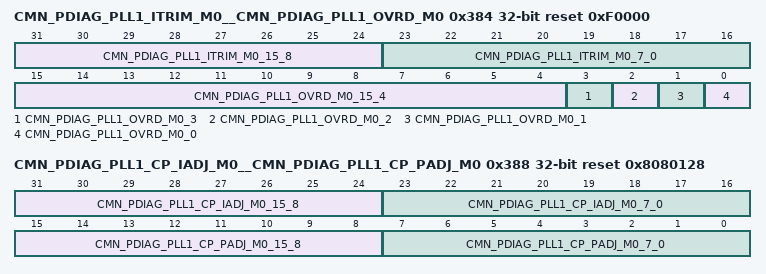
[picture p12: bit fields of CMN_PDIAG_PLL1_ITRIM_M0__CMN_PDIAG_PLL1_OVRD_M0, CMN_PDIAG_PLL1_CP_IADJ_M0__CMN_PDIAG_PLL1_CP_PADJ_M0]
0x384 CMN_PDIAG_PLL1_ITRIM_M0__CMN_PDIAG_PLL1_OVRD_M0 reset 0xF0000 — PLL 1 override register mode 0
  [31:24] CMN_PDIAG_PLL1_ITRIM_M0_15_8 ro — Reserved
  [23:16] CMN_PDIAG_PLL1_ITRIM_M0_7_0 rw — PLL VCO bias current trim code: Controls the tank currents in the PLL LC tank circuit.
  [15:4] CMN_PDIAG_PLL1_OVRD_M0_15_4 ro — Reserved
  [3] CMN_PDIAG_PLL1_OVRD_M0_3 rw — PLL VCO calibration enable override enable: When active (1'b1), the PLL VCO calibration enable override bit in this register, can be used to directly control the enable of the VCO calibration function in the PLL (instead of the VCO calibration module).
  [2] CMN_PDIAG_PLL1_OVRD_M0_2 rw — PLL VCO calibration enable override: When enabled by the PLL VCO calibration enable override enable bit in this register, this bit will directly control the enable of the VCO calibration function in the PLL.
  [1] CMN_PDIAG_PLL1_OVRD_M0_1 rw — PLL phase lock detect enable : Enables the diagnostic PLL phase lock detect function in the analog.
  [0] CMN_PDIAG_PLL1_OVRD_M0_0 ro — PLL phase lock detected : When enabled by the PLL phase lock detect enable bit in this register, this bit indicates that a PLL phase lock has been detected.
0x388 CMN_PDIAG_PLL1_CP_IADJ_M0__CMN_PDIAG_PLL1_CP_PADJ_M0 rw reset 0x8080128 — PLL 1 charge pump proportional path adjust register mode 0
  [31:24] CMN_PDIAG_PLL1_CP_IADJ_M0_15_8 — PLL charge pump integral path capacitance adjust: Adjusts the charge pump integral path capacitance, by driving the cmnda_pll1_cp_int_cap_adj signal going to the analog.
  [23:16] CMN_PDIAG_PLL1_CP_IADJ_M0_7_0 — PLL charge pump integral path current adjust: Adjusts the charge pump integral path current, by driving the cmnda_pll1_cp_int_cur_adj signal going to the analog.
  [15:8] CMN_PDIAG_PLL1_CP_PADJ_M0_15_8 — PLL charge pump proportional path capacitance adjust: Adjusts the charge pump proportional path capacitance, by driving the cmnda_pll1_cp_prop_cap_adj signal going to the analog.
  [7:0] CMN_PDIAG_PLL1_CP_PADJ_M0_7_0 — PLL charge pump proportional path current adjust: Adjusts the charge pump proportional path current, by driving the cmnda_pll1_cp_prop_cur_adj signal going to the analog.
